# NAVSS0_UDMASS_INTA_0_UDMASS_INTA0_CFG_MCAST register map
Vendor: Texas Instruments
Peripheral module from a debugger description file (folder J721S2).
Registers are 64-bit, read-write, reset 0xFFFF0000FFFF unless marked. A register's access mark holds for its fields unless they carry their own. Offsets are as the file gives them; lines under a group give offsets from that group; [hi:lo] are bit positions; {n}, {i} and the like mark numbered series; 'fields as' and 'values as' point back to an identical list; <NAME> marks a mode.

## NAVSS0_UDMASS_INTA_0_UDMASS_INTA0_CFG_MCAST
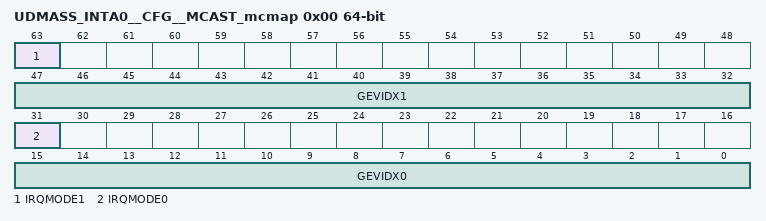
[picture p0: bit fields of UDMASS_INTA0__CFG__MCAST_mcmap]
0x00 UDMASS_INTA0__CFG__MCAST_mcmap — This register determines how ingress global events from the ingress global event ETL are written out to the two egress global event ETL intefaces. The index of each of the two egress events is stored in this register, which is selected based in the ingress event index value.
  [63] IRQMODE1 — IRQ Mode Flag 1. When set, this register act like a mapper with bitnum in 37:32 and regnum in 46:38.
  [47:32] GEVIDX1 — Global event index 1. This field specifies the index of the outgoing global event on ETL 1. Set to 0xFFFF to disable.
  [31] IRQMODE0 — IRQ Mode Flag 0. When set, this register act like a mapper with bitnum in 5:0 and regnum in 14:6.
  [15:0] GEVIDX0 — Global event index 0. This field specifies the index of the outgoing global event on ETL 0. Set to 0xFFFF to disable.
